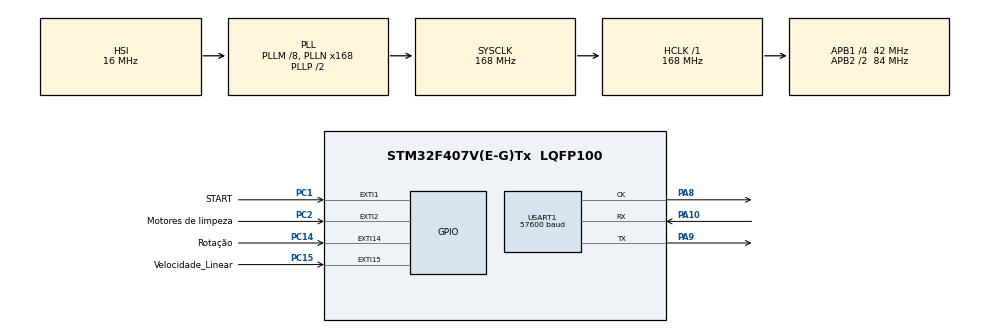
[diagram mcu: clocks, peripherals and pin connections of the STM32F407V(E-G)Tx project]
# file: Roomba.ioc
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Mcu.Family=STM32F4
Mcu.Name=STM32F407V(E-G)Tx
Mcu.Package=LQFP100
NVIC.EXTI15_10_IRQn=true\:0\:0\:false\:false\:true\:true\:true
NVIC.EXTI1_IRQn=true\:0\:0\:false\:false\:true\:true\:true
NVIC.EXTI2_IRQn=true\:0\:0\:false\:false\:true\:true\:true
NVIC.PriorityGroup=NVIC_PRIORITYGROUP_4
NVIC.TIM3_IRQn=true\:0\:0\:false\:false\:true\:true\:true
PA10.Mode=Synchronous
PA10.Signal=USART1_RX
PA13.Mode=Serial_Wire
PA13.Signal=SYS_JTMS-SWDIO
PA14.Mode=Serial_Wire
PA14.Signal=SYS_JTCK-SWCLK
PA8.Mode=Synchronous
PA8.Signal=USART1_CK
PA9.Mode=Synchronous
PA9.Signal=USART1_TX
PC1.GPIO_Label=START
PC1.GPIO_ModeDefaultEXTI=GPIO_MODE_IT_RISING_FALLING
PC1.Signal=GPXTI1
PC14-OSC32_IN.GPIO_Label=Rota\u00E7\u00E3o
PC14-OSC32_IN.GPIO_ModeDefaultEXTI=GPIO_MODE_IT_RISING_FALLING
PC14-OSC32_IN.Signal=GPXTI14
PC15-OSC32_OUT.GPIO_Label=Velocidade_Linear
PC15-OSC32_OUT.GPIO_ModeDefaultEXTI=GPIO_MODE_IT_RISING_FALLING
PC15-OSC32_OUT.Signal=GPXTI15
PC2.GPIO_Label=Motores de limpeza
PC2.GPIO_ModeDefaultEXTI=GPIO_MODE_IT_RISING_FALLING
PC2.Signal=GPXTI2
PH0-OSC_IN.Mode=HSE-External-Oscillator
PH0-OSC_IN.Signal=RCC_OSC_IN
PH1-OSC_OUT.Mode=HSE-External-Oscillator
PH1-OSC_OUT.Signal=RCC_OSC_OUT
ProjectManager.HeapSize=0x200
ProjectManager.StackSize=0x400
ProjectManager.TargetToolchain=TrueSTUDIO
RCC.48MHZClocksFreq_Value=84000000
RCC.AHBFreq_Value=168000000
RCC.APB1CLKDivider=RCC_HCLK_DIV4
RCC.APB1Freq_Value=42000000
RCC.APB1TimFreq_Value=84000000
RCC.APB2CLKDivider=RCC_HCLK_DIV2
RCC.APB2Freq_Value=84000000
RCC.APB2TimFreq_Value=168000000
RCC.CortexFreq_Value=168000000
RCC.HCLKFreq_Value=168000000
RCC.HSE_VALUE=25000000
RCC.HSI_VALUE=16000000
RCC.LSE_VALUE=32768
RCC.PLLM=8
RCC.PLLN=168
RCC.SYSCLKFreq_VALUE=168000000
RCC.SYSCLKSource=RCC_SYSCLKSOURCE_PLLCLK
RCC.VCOOutputFreq_Value=336000000
TIM3.Period=9
TIM3.Prescaler=480
USART1.BaudRate=57600
USART1.VirtualMode=VM_SYNC
VP_TIM3_VS_ClockSourceINT.Mode=Internal
board=custom

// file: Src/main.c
/* USER CODE BEGIN Header */
/**
  ******************************************************************************
  * @file           : main.c
  * @brief          : Main program body
  ******************************************************************************
  * @attention
  *
  * <h2><center>&copy; Copyright (c) 2019 STMicroelectronics.
  * All rights reserved.</center></h2>
  *
  * This software component is licensed by ST under BSD 3-Clause license,
  * the "License"; You may not use this file except in compliance with the
  * License. You may obtain a copy of the License at:
  *                        opensource.org/licenses/BSD-3-Clause
  *
  ******************************************************************************
  */
/* USER CODE END Header */

#include "main.h"

TIM_HandleTypeDef htim3;

USART_HandleTypeDef husart1;

void SystemClock_Config(void);
static void MX_GPIO_Init(void);
static void MX_TIM3_Init(void);
static void MX_USART1_Init(void);

//Variaveis globais para medir o sinal de velocidade linear
int Velo_TimeUp = 0;
int Velo_TimeFull = 1;
int Velo_Up = 0;
int Velo_DutyCycle = 0;
//Variaveis globais para medir o sinal de Rotação
int Rota_TimeUp = 0;
int Rota_TimeFull = 1;
int Rota_Up = 0;
int Rota_DutyCycle = 0;
//Variaveis globais para medir o sinal de Motores de Limpeza
int Limpa_TimeUp = 0;
int Limpa_TimeFull = 1;
int Limpa_Up = 0;
int Limpa_DutyCycle = 0;
int Limpa = 0;
//Variaveis globais para medir o sinal de START
int START_TimeUp = 0;
int START_TimeFull = 1;
int START_Up = 0;
int START_DutyCycle = 0;
//Sinal global de start
int START = 0;

int main(void)
{

  /* MCU Configuration--------------------------------------------------------*/

  /* Reset of all peripherals, Initializes the Flash interface and the Systick. */
  HAL_Init();

  /* Configure the system clock */
  SystemClock_Config();

  /* Initialize all configured peripherals */
  MX_GPIO_Init();
  MX_TIM3_Init();
  MX_USART1_Init();
  /* USER CODE BEGIN 2 */
  HAL_USART_Transmit(husart1, 0x80,0,0);//manda o comando start para o roomba iniciando o SCI

  /*SINCERAMENTE EU NAO SEI SE ESSA FORMA DE MANDAR COMANDOS SERIAIS VAI FUNCIONAR
   * MAS PELOMENOS OS VALORES A SEREM MANDADOS ESTÃO CERTOS AO LONGO DO CÓDIGO */

  /* USER CODE END 2 */

  /* Infinite loop */
  while (1)
  {

    /* USER CODE BEGIN 3 */
	  /*POWER SAFE MAJOR
	   FLUXO DO PROGRAMA NO
	   STM32F4XX_IT.C
	   */
	  HAL_Delay(100);
	  HAL_PWR_EnterSLEEPMode(PWR_LOWPOWERREGULATOR_ON , PWR_SLEEPENTRY_WFI);
  }
  /* USER CODE END 3 */
}

void SystemClock_Config(void)
{
  RCC_OscInitTypeDef RCC_OscInitStruct = {0};
  RCC_ClkInitTypeDef RCC_ClkInitStruct = {0};

  /** Configure the main internal regulator output voltage
  */
  __HAL_RCC_PWR_CLK_ENABLE();
  __HAL_PWR_VOLTAGESCALING_CONFIG(PWR_REGULATOR_VOLTAGE_SCALE1);
  /** Initializes the CPU, AHB and APB busses clocks
  */
  RCC_OscInitStruct.OscillatorType = RCC_OSCILLATORTYPE_HSI;
  RCC_OscInitStruct.HSIState = RCC_HSI_ON;
  RCC_OscInitStruct.HSICalibrationValue = RCC_HSICALIBRATION_DEFAULT;
  RCC_OscInitStruct.PLL.PLLState = RCC_PLL_ON;
  RCC_OscInitStruct.PLL.PLLSource = RCC_PLLSOURCE_HSI;
  RCC_OscInitStruct.PLL.PLLM = 8;
  RCC_OscInitStruct.PLL.PLLN = 168;
  RCC_OscInitStruct.PLL.PLLP = RCC_PLLP_DIV2;
  RCC_OscInitStruct.PLL.PLLQ = 4;
  if (HAL_RCC_OscConfig(&RCC_OscInitStruct) != HAL_OK)
  {
    Error_Handler();
  }
  /** Initializes the CPU, AHB and APB busses clocks
  */
  RCC_ClkInitStruct.ClockType = RCC_CLOCKTYPE_HCLK|RCC_CLOCKTYPE_SYSCLK
                              |RCC_CLOCKTYPE_PCLK1|RCC_CLOCKTYPE_PCLK2;
  RCC_ClkInitStruct.SYSCLKSource = RCC_SYSCLKSOURCE_PLLCLK;
  RCC_ClkInitStruct.AHBCLKDivider = RCC_SYSCLK_DIV1;
  RCC_ClkInitStruct.APB1CLKDivider = RCC_HCLK_DIV4;
  RCC_ClkInitStruct.APB2CLKDivider = RCC_HCLK_DIV2;

  if (HAL_RCC_ClockConfig(&RCC_ClkInitStruct, FLASH_LATENCY_5) != HAL_OK)
  {
    Error_Handler();
  }
}

static void MX_TIM3_Init(void)
{

  TIM_ClockConfigTypeDef sClockSourceConfig = {0};
  TIM_MasterConfigTypeDef sMasterConfig = {0};

  htim3.Instance = TIM3;
  htim3.Init.Prescaler = 480;
  htim3.Init.CounterMode = TIM_COUNTERMODE_UP;
  htim3.Init.Period = 9;
  htim3.Init.ClockDivision = TIM_CLOCKDIVISION_DIV1;
  htim3.Init.AutoReloadPreload = TIM_AUTORELOAD_PRELOAD_DISABLE;
  if (HAL_TIM_Base_Init(&htim3) != HAL_OK)
  {
    Error_Handler();
  }
  sClockSourceConfig.ClockSource = TIM_CLOCKSOURCE_INTERNAL;
  if (HAL_TIM_ConfigClockSource(&htim3, &sClockSourceConfig) != HAL_OK)
  {
    Error_Handler();
  }
  sMasterConfig.MasterOutputTrigger = TIM_TRGO_RESET;
  sMasterConfig.MasterSlaveMode = TIM_MASTERSLAVEMODE_DISABLE;
  if (HAL_TIMEx_MasterConfigSynchronization(&htim3, &sMasterConfig) != HAL_OK)
  {
    Error_Handler();
  }

}

static void MX_USART1_Init(void)
{

  husart1.Instance = USART1;
  husart1.Init.BaudRate = 57600;
  husart1.Init.WordLength = USART_WORDLENGTH_8B;
  husart1.Init.StopBits = USART_STOPBITS_1;
  husart1.Init.Parity = USART_PARITY_NONE;
  husart1.Init.Mode = USART_MODE_TX_RX;
  husart1.Init.CLKPolarity = USART_POLARITY_LOW;
  husart1.Init.CLKPhase = USART_PHASE_1EDGE;
  husart1.Init.CLKLastBit = USART_LASTBIT_DISABLE;
  if (HAL_USART_Init(&husart1) != HAL_OK)
  {
    Error_Handler();
  }

}

static void MX_GPIO_Init(void)
{
  GPIO_InitTypeDef GPIO_InitStruct = {0};

  /* GPIO Ports Clock Enable */
  __HAL_RCC_GPIOE_CLK_ENABLE();
  __HAL_RCC_GPIOC_CLK_ENABLE();
  __HAL_RCC_GPIOH_CLK_ENABLE();
  __HAL_RCC_GPIOA_CLK_ENABLE();
  __HAL_RCC_GPIOB_CLK_ENABLE();
  __HAL_RCC_GPIOD_CLK_ENABLE();

  /*Configure GPIO pins : PE2 PE3 PE4 PE5
                           PE6 PE7 PE8 PE9
                           PE10 PE11 PE12 PE13
                           PE14 PE15 PE0 PE1 */
  GPIO_InitStruct.Pin = GPIO_PIN_2|GPIO_PIN_3|GPIO_PIN_4|GPIO_PIN_5
                          |GPIO_PIN_6|GPIO_PIN_7|GPIO_PIN_8|GPIO_PIN_9
                          |GPIO_PIN_10|GPIO_PIN_11|GPIO_PIN_12|GPIO_PIN_13
                          |GPIO_PIN_14|GPIO_PIN_15|GPIO_PIN_0|GPIO_PIN_1;
  GPIO_InitStruct.Mode = GPIO_MODE_ANALOG;
  GPIO_InitStruct.Pull = GPIO_NOPULL;
  HAL_GPIO_Init(GPIOE, &GPIO_InitStruct);

  /*Configure GPIO pins : PC13 PC0 PC3 PC4
                           PC5 PC6 PC7 PC8
                           PC9 PC10 PC11 PC12 */
  GPIO_InitStruct.Pin = GPIO_PIN_13|GPIO_PIN_0|GPIO_PIN_3|GPIO_PIN_4
                          |GPIO_PIN_5|GPIO_PIN_6|GPIO_PIN_7|GPIO_PIN_8
                          |GPIO_PIN_9|GPIO_PIN_10|GPIO_PIN_11|GPIO_PIN_12;
  GPIO_InitStruct.Mode = GPIO_MODE_ANALOG;
  GPIO_InitStruct.Pull = GPIO_NOPULL;
  HAL_GPIO_Init(GPIOC, &GPIO_InitStruct);

  /*Configure GPIO pins : Rota__o_Pin Velocidade_Linear_Pin START_Pin Motores_de_limpeza_Pin */
  GPIO_InitStruct.Pin = Rota__o_Pin|Velocidade_Linear_Pin|START_Pin|Motores_de_limpeza_Pin;
  GPIO_InitStruct.Mode = GPIO_MODE_IT_RISING_FALLING;
  GPIO_InitStruct.Pull = GPIO_NOPULL;
  HAL_GPIO_Init(GPIOC, &GPIO_InitStruct);

  /*Configure GPIO pins : PA0 PA1 PA2 PA3
                           PA4 PA5 PA6 PA7
                           PA11 PA12 PA15 */
  GPIO_InitStruct.Pin = GPIO_PIN_0|GPIO_PIN_1|GPIO_PIN_2|GPIO_PIN_3
                          |GPIO_PIN_4|GPIO_PIN_5|GPIO_PIN_6|GPIO_PIN_7
                          |GPIO_PIN_11|GPIO_PIN_12|GPIO_PIN_15;
  GPIO_InitStruct.Mode = GPIO_MODE_ANALOG;
  GPIO_InitStruct.Pull = GPIO_NOPULL;
  HAL_GPIO_Init(GPIOA, &GPIO_InitStruct);

  /*Configure GPIO pins : PB0 PB1 PB2 PB10
                           PB11 PB12 PB13 PB14
                           PB15 PB3 PB4 PB5
                           PB6 PB7 PB8 PB9 */
  GPIO_InitStruct.Pin = GPIO_PIN_0|GPIO_PIN_1|GPIO_PIN_2|GPIO_PIN_10
                          |GPIO_PIN_11|GPIO_PIN_12|GPIO_PIN_13|GPIO_PIN_14
                          |GPIO_PIN_15|GPIO_PIN_3|GPIO_PIN_4|GPIO_PIN_5
                          |GPIO_PIN_6|GPIO_PIN_7|GPIO_PIN_8|GPIO_PIN_9;
  GPIO_InitStruct.Mode = GPIO_MODE_ANALOG;
  GPIO_InitStruct.Pull = GPIO_NOPULL;
  HAL_GPIO_Init(GPIOB, &GPIO_InitStruct);

  /*Configure GPIO pins : PD8 PD9 PD10 PD11
                           PD12 PD13 PD14 PD15
                           PD0 PD1 PD2 PD3
                           PD4 PD5 PD6 PD7 */
  GPIO_InitStruct.Pin = GPIO_PIN_8|GPIO_PIN_9|GPIO_PIN_10|GPIO_PIN_11
                          |GPIO_PIN_12|GPIO_PIN_13|GPIO_PIN_14|GPIO_PIN_15
                          |GPIO_PIN_0|GPIO_PIN_1|GPIO_PIN_2|GPIO_PIN_3
                          |GPIO_PIN_4|GPIO_PIN_5|GPIO_PIN_6|GPIO_PIN_7;
  GPIO_InitStruct.Mode = GPIO_MODE_ANALOG;
  GPIO_InitStruct.Pull = GPIO_NOPULL;
  HAL_GPIO_Init(GPIOD, &GPIO_InitStruct);

  /* EXTI interrupt init*/
  HAL_NVIC_SetPriority(EXTI1_IRQn, 0, 0);
  HAL_NVIC_EnableIRQ(EXTI1_IRQn);

  HAL_NVIC_SetPriority(EXTI2_IRQn, 0, 0);
  HAL_NVIC_EnableIRQ(EXTI2_IRQn);

  HAL_NVIC_SetPriority(EXTI15_10_IRQn, 0, 0);
  HAL_NVIC_EnableIRQ(EXTI15_10_IRQn);

}

void Error_Handler(void)
{
}

/************************ (C) COPYRIGHT STMicroelectronics *****END OF FILE****/
